# CY8C5287AXI_LP095 register map
File version: 0.1
CY8C52LP
Registers are 8-bit, read-write, no defined reset value unless marked. A register's access mark holds for its fields unless they carry their own. Offsets are from the block's base; lines under a group give offsets from that group; [hi:lo] are bit positions; {n}, {i} and the like mark numbered series; 'fields as' and 'values as' point back to an identical list; <NAME> marks a mode.

## Memory map
0x00000000 LED_BrtPWM
0x00000000 UART
0x00000000 USBUART — USBFS
0x00000000 CSD — CapSense
0x00000000 CSD_IdacCH0
0x00000000 CSD_CompCH0
0x00000000 Disp_BrtPWM
0x40006575 Disp_COM_Sel

## LED_BrtPWM
Base 0x00000000
0x400043A3 LED_BrtPWM_GLOBAL_ENABLE — PM.ACT.CFG
  [3:0] en_timer — Enable timer/counters.
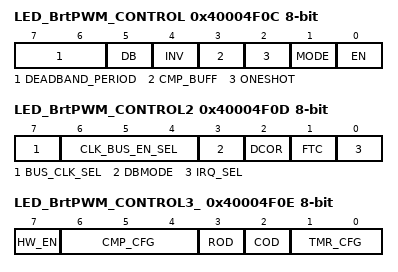
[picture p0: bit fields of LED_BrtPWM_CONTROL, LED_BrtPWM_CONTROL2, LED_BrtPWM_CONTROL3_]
0x40004F0C LED_BrtPWM_CONTROL — TMRx.CFG0
  [7:6] DEADBAND_PERIOD
  [5] DB — Deadband mode--Deadband phases phi1 and phi2 are outputted on CMP and TC output pins respectively.
    0=Timer (CMP and TC are output.); 1=Deadband (PHI1 (instead of CMP) and PHI2 (instead of TC) are output.)
  [4] INV — Invert sense of TIMEREN signal
  [3] CMP_BUFF — Buffer compare register. Compare register updates only on timer terminal count.
  [2] ONESHOT — Timer stops upon reaching stop condition defined by TMR_CFG bits. Can be restarted by asserting TIMER RESET or disabling and re-enabling block.
  [1] MODE ro — Mode. (0 = Timer; 1 = Comparator)
    0=Timer mode. CNT/CMP register holds timer count value.; 1=Comparator mode. CNT/CMP register holds comparator threshold value.
  [0] EN — Enables timer/comparator.
0x40004F0D LED_BrtPWM_CONTROL2 — TMRx.CFG1
  [7] BUS_CLK_SEL — Bus Clock selection.
  [6:4] CLK_BUS_EN_SEL — Digital Global Clock selection.
  [3] DBMODE — Deadband mode (asynchronous/synchronous). CMP output pin is also affected when not in deadband mode (CFG0.DEADBAND).
  [2] DCOR — Disable Clear on Read (DCOR) of Status Register SR0.
  [1] FTC — First Terminal Count (FTC). Setting this bit forces a single pulse on the TC pin when first enabled.
    0=Disable_FTC (Disable the single cycle pulse, which signifies the timer is starting.); 1=Enable_FTC (Enable the single cycle pulse, which signifies the timer is starting.)
  [0] IRQ_SEL — Irq selection. (0 = raw interrupts; 1 = status register interrupts)
0x40004F0E LED_BrtPWM_CONTROL3_ — TMRx.CFG2
  [7] HW_EN — When set Timer Enable controls counting.
  [6:4] CMP_CFG — Comparator configurations
    0=Equal (Compare Equal); 1=Less_than (Compare Less Than); 2=Less_than_or_equal (Compare Less Than or Equal .); 3=Greater (Compare Greater Than .); 4=Greater_than_or_equal (Compare Greater Than or Equal)
  [3] ROD — Reset On Disable (ROD). Resets internal state of output logic
  [2] COD — Clear On Disable (COD). Clears or gates outputs to zero.
  [1:0] TMR_CFG — Timer configuration (MODE = 0): 000 = Continuous; 001 = Pulsewidth; 010 = Period; 011 = Stop on IRQ
    0=Continuous (Timer runs while EN bit of CFG0 register is set to '1'.); 1=Pulsewidth (Timer runs from positive to negative edge of TIMEREN.); 2=Period (Timer runs from positive to positive edge of TIMEREN.); 3=Irq (Timer runs until IRQ.)
0x40004F10 LED_BrtPWM_PERIOD 16-bit — TMRx.PER0 - Assigned Period
0x40004F12 LED_BrtPWM_COMPARE 16-bit — TMRx.CNT_CMP0 - Assigned Compare Value

## UART
Base 0x00000000
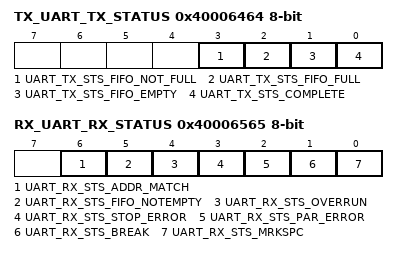
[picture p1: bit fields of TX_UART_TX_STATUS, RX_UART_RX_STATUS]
0x40006464 TX_UART_TX_STATUS — TX status register
  [3] UART_TX_STS_FIFO_NOT_FULL ro, [2] UART_TX_STS_FIFO_FULL ro, [1] UART_TX_STS_FIFO_EMPTY ro, [0] UART_TX_STS_COMPLETE ro
0x40006525 RX_UART_RX_ADDRESS1 — RX Address1 Register
0x40006535 RX_UART_RX_ADDRESS2 — RX Address2 Register
0x40006545 RX_UART_RX_DATA — RX Data Register
0x40006547 TX_UART_TX_DATA — TX Data Register
0x40006565 RX_UART_RX_STATUS — RX status register
  [6] UART_RX_STS_ADDR_MATCH ro, [5] UART_RX_STS_FIFO_NOTEMPTY ro, [4] UART_RX_STS_OVERRUN ro, [3] UART_RX_STS_STOP_ERROR ro, [2] UART_RX_STS_PAR_ERROR ro, [1] UART_RX_STS_BREAK ro, [0] UART_RX_STS_MRKSPC ro

## USBUART — USBFS
Base 0x00000000
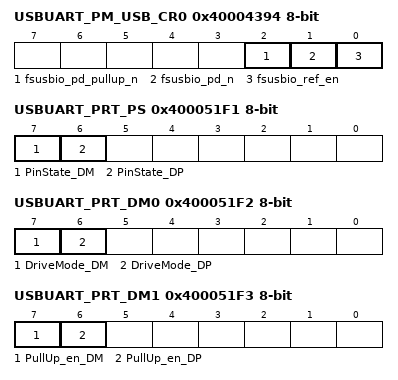
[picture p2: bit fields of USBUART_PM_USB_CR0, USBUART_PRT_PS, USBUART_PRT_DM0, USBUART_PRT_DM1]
0x40004394 USBUART_PM_USB_CR0 — USB Power Mode Control Register 0
  [2] fsusbio_pd_pullup_n, [1] fsusbio_pd_n, [0] fsusbio_ref_en
0x400043A5 USBUART_PM_ACT_CFG — Active Power Mode Configuration Register
0x400043B5 USBUART_PM_STBY_CFG — Standby Power Mode Configuration Register
0x400051F1 USBUART_PRT_PS — Port Pin State Register
  [7] PinState_DM ro, [6] PinState_DP ro
0x400051F2 USBUART_PRT_DM0 — Port Drive Mode Register
  [7] DriveMode_DM, [6] DriveMode_DP
0x400051F3 USBUART_PRT_DM1 — Port Drive Mode Register
  [7] PullUp_en_DM, [6] PullUp_en_DP
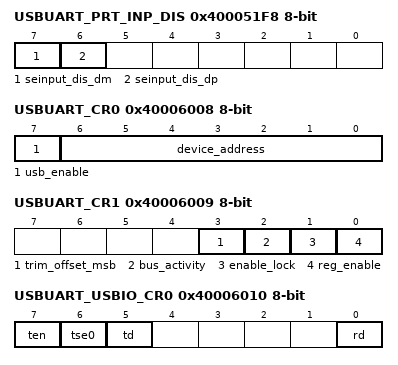
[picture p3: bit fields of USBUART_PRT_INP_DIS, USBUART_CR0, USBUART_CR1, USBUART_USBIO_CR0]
0x400051F8 USBUART_PRT_INP_DIS — Input buffer disable override
  [7] seinput_dis_dm, [6] seinput_dis_dp
0x40006000 USBUART_EP0_DR0 — bmRequestType
0x40006001 USBUART_EP0_DR1 — bRequest
0x40006002 USBUART_EP0_DR2 — wValueLo
0x40006003 USBUART_EP0_DR3 — wValueHi
0x40006004 USBUART_EP0_DR4 — wIndexLo
0x40006005 USBUART_EP0_DR5 — wIndexHi
0x40006006 USBUART_EP0_DR6 — lengthLo
0x40006007 USBUART_EP0_DR7 — lengthHi
0x40006008 USBUART_CR0 — USB Control Register 0
  [7] usb_enable, [6:0] device_address ro
0x40006009 USBUART_CR1 — USB Control Register 1
  [3] trim_offset_msb, [2] bus_activity, [1] enable_lock, [0] reg_enable
{0x40005FFE+0x10*i} USBUART_SIE_EP{i}_CR0 (i=1..8) — The Endpoint{i} Control Register
0x40006010 USBUART_USBIO_CR0 — USBIO Control Register 0
  [7] ten, [6] tse0, [5] td, [0] rd ro
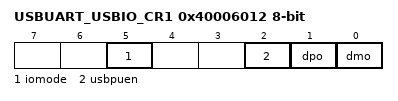
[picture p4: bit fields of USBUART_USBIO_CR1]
0x40006012 USBUART_USBIO_CR1 — USBIO Control Register 1
  [5] iomode, [2] usbpuen, [1] dpo ro, [0] dmo ro
0x4000608C USBUART_BUF_SIZE — Dedicated Endpoint Buffer Size Register
0x4000608E USBUART_EP_ACTIVE — Endpoint Active Indication Register
0x4000608F USBUART_EP_TYPE — Endpoint Type (IN/OUT) Indication
0x4000609D USBUART_USB_CLK_EN — USB Block Clock Enable Register
